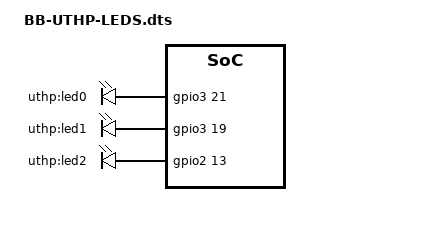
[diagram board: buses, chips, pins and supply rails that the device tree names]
/* PLC4TRUCKSDuck (c) 2024 National Motor Freight Traffic Association
 *
 * Permission is hereby granted, free of charge, to any person obtaining a copy
 * of this software and associated documentation files (the "Software"), to deal
 * in the Software without restriction, including without limitation the rights
 * to use, copy, modify, merge, publish, distribute, sublicense, and/or sell
 * copies of the Software, and to permit persons to whom the Software is
 * furnished to do so, subject to the following conditions:
 *
 * The above copyright notice and this permission notice shall be included in all
 * copies or substantial portions of the Software.
 *
 * THE SOFTWARE IS PROVIDED "AS IS", WITHOUT WARRANTY OF ANY KIND, EXPRESS OR
 * IMPLIED, INCLUDING BUT NOT LIMITED TO THE WARRANTIES OF MERCHANTABILITY,
 * FITNESS FOR A PARTICULAR PURPOSE AND NONINFRINGEMENT. IN NO EVENT SHALL THE
 * AUTHORS OR COPYRIGHT HOLDERS BE LIABLE FOR ANY CLAIM, DAMAGES OR OTHER
 * LIABILITY, WHETHER IN AN ACTION OF CONTRACT, TORT OR OTHERWISE, ARISING FROM,
 * OUT OF OR IN CONNECTION WITH THE SOFTWARE OR THE USE OR OTHER DEALINGS IN THE
 * SOFTWARE.
 */

/dts-v1/;
/plugin/;

/ {
    compatible = "ti,beaglebone", "ti,beaglebone-black";
    part-number = "UTHP-LEDS";

    fragment@0 {
        target = <&am33xx_pinmux>;
        __overlay__ {
            uthp_led_pins: pinmux_uthp_led_pins {
                pinctrl-single,pins = <
                    0x1ac 0x0f  
                    0x1a4 0x0f
                    0x0bc 0x0f
                >;
            };
        };
    };

    fragment@1 {
        target = <&ocp>;
        __overlay__ {
            uthp_leds {
                compatible = "gpio-leds";
                status = "okay";
                pinctrl-names = "default";
                pinctrl-0 = <&uthp_led_pins>;

                led0 {
                    label = "uthp:led0";
                    gpios = <&gpio3 21 0>;
                    default-state = "on";
                    linux,default-trigger = "heartbeat";
                };

                /* This LED is used to indicate CAN activity */
                /* It is triggered by the CAN0 interface */
                /* Feel free to change the trigger source */
                led1 {
                    label = "uthp:led1";
                    gpios = <&gpio3 19 0>;
                    default-state = "off";
                    linux,default-trigger = "netdev";
                };

                /* This LED is used to indicate J1708 activity */
                /* It is triggered using the PLC4TRUCKSDUC interface */
                led2 {
                    label = "uthp:led2";
                    gpios = <&gpio2 13 0>;
                    default-state = "off";
                    linux,default-trigger = "none";
                };
            };
        };
    };
};
